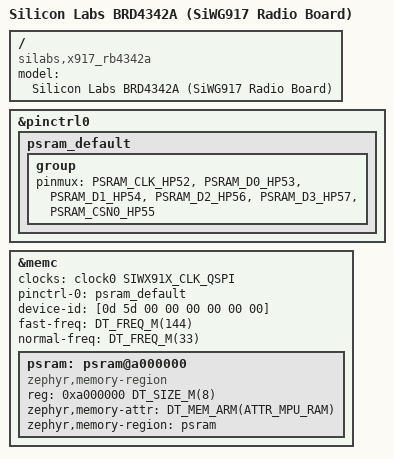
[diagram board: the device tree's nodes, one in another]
/*
 * Copyright (c) 2023 Antmicro
 * Copyright (c) 2025 Silicon Laboratories Inc.
 * SPDX-License-Identifier: Apache-2.0
 */

/dts-v1/;
#include <zephyr/dt-bindings/memory-attr/memory-attr-arm.h>
#include <zephyr/dt-bindings/pinctrl/silabs/siwx91x-pinctrl.h>
#include "common.dtsi"

/ {
	model = "Silicon Labs BRD4342A (SiWG917 Radio Board)";
	compatible = "silabs,x917_rb4342a", "silabs,siwg917";
};

&pinctrl0 {
	psram_default: psram_default {
		group {
			pinmux = <PSRAM_CLK_HP52>,
				 <PSRAM_D0_HP53>,
				 <PSRAM_D1_HP54>,
				 <PSRAM_D2_HP56>,
				 <PSRAM_D3_HP57>,
				 <PSRAM_CSN0_HP55>;
		};
	};
};

&memc {
	clocks = <&clock0 SIWX91X_CLK_QSPI>;
	pinctrl-0 = <&psram_default>;
	pinctrl-names = "default";
	device-id = [0d 5d 00 00 00 00 00 00];
	fast-freq = <DT_FREQ_M(144)>;
	normal-freq = <DT_FREQ_M(33)>;
	status = "okay";

	psram: psram@a000000 {
		compatible = "zephyr,memory-region", "mmio-sram";
		reg = <0xa000000 DT_SIZE_M(8)>;
		zephyr,memory-attr = <DT_MEM_ARM(ATTR_MPU_RAM)>;
		zephyr,memory-region = "psram";
	};
};
